# ESP32-H2 register map
Vendor: ESPRESSIF SYSTEMS (SHANGHAI) CO., LTD.; Series: ESP32 H-Series; File version: 11
CPU: RV32IMAC r0p0, little endian, no MPU, no FPU, 0 interrupt priority bits
Address unit: 32 bits
Registers are 32-bit, read-write, reset 0x0 unless marked. A register's access mark holds for its fields unless they carry their own. Offsets are from the block's base; [hi:lo] are bit positions; {n}, {i} and the like mark numbered series.

## ECC — ECC (ECC Hardware Accelerator)
Base 0x6008B000
0x0C MULT_INT_RAW ro — ECC interrupt raw register, valid in level.
  [0] CALC_DONE_INT_RAW — The raw interrupt status bit for the ecc_calc_done_int interrupt
0x10 MULT_INT_ST ro — ECC interrupt status register.
  [0] CALC_DONE_INT_ST — The masked interrupt status bit for the ecc_calc_done_int interrupt
0x14 MULT_INT_ENA — ECC interrupt enable register.
  [0] CALC_DONE_INT_ENA — The interrupt enable bit for the ecc_calc_done_int interrupt
0x18 MULT_INT_CLR wo — ECC interrupt clear register.
  [0] CALC_DONE_INT_CLR — Set this bit to clear the ecc_calc_done_int interrupt
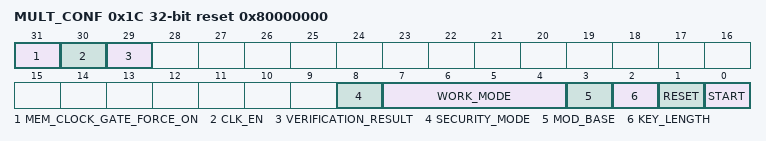
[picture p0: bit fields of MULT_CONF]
0x1C MULT_CONF access per field reset 0x80000000 — ECC configure register
  [31] MEM_CLOCK_GATE_FORCE_ON rw — ECC memory clock gate force on register
  [30] CLK_EN rw — Write 1 to force on register clock gate.
  [29] VERIFICATION_RESULT ro — The verification result bit of ECC Accelerator, only valid when calculation is done.
  [8] SECURITY_MODE rw — Reserved
  [7:4] WORK_MODE rw — The work mode bits of ECC Accelerator. 0: Point Mult Mode. 1: Reserved. 2: Point verification mode. 3: Point Verif+mult mode. 4: Jacobian Point Mult Mode. 5: Point Add Mode. 6: Jacobian Point Verification Mode. 7: Point Verif + Jacobian Mult Mode. 8: mod addition. 9. mod substraction. 10: mod multiplication. 11: mod division.
  [3] MOD_BASE rw — The mod base of mod operation, only valid in work_mode 8-11. 0: n(order of curve). 1: p(mod base of curve)
  [2] KEY_LENGTH rw — The key length mode bit of ECC Accelerator. 0: P-192. 1: P-256.
  [1] RESET wo — Write 1 to reset ECC Accelerator.
  [0] START rw — Write 1 to start caculation of ECC Accelerator. This bit will be self-cleared after the caculatrion is done.
0xFC MULT_DATE reset 0x2207180 — Version control register
  [27:0] DATE — ECC mult version control register
{0x100+4i} K_MEM[{i}] (i=0..7) access not given — The memory that stores k.
{0x120+4i} PX_MEM[{i}] (i=0..7) access not given — The memory that stores Px.
{0x140+4i} PY_MEM[{i}] (i=0..7) access not given — The memory that stores Py.
{0x160+4i} QX_MEM{i} (i=0..7) — The memory that stores Qx
{0x180+4i} QY_MEM{i} (i=0..7) — The memory that stores Qy
{0x1A0+4i} QZ_MEM{i} (i=0..7) — The memory that stores Qz

## GPIO — General Purpose Input/Output
Base 0x60091000
0x00 BT_SELECT — GPIO bit select register
  [31:0] BT_SEL
0x04 OUT — GPIO output register for GPIO0-31
  [31:0] DATA_ORIG
0x08 OUT_W1TS wo — GPIO output set register for GPIO0-31
0x0C OUT_W1TC wo — GPIO output clear register for GPIO0-31
0x1C SDIO_SELECT — GPIO sdio select register
  [7:0] SDIO_SEL
0x20 ENABLE — GPIO output enable register for GPIO0-31
  [31:0] DATA
0x24 ENABLE_W1TS wo — GPIO output enable set register for GPIO0-31
0x28 ENABLE_W1TC wo — GPIO output enable clear register for GPIO0-31
0x38 STRAP ro — pad strapping register
  [15:0] STRAPPING
0x3C IN ro — GPIO input register for GPIO0-31
  [31:0] DATA_NEXT
0x44 STATUS — GPIO interrupt status register for GPIO0-31
  [31:0] INTERRUPT
0x48 STATUS_W1TS wo — GPIO interrupt status set register for GPIO0-31
0x4C STATUS_W1TC wo — GPIO interrupt status clear register for GPIO0-31
0x5C PCPU_INT ro — GPIO PRO_CPU interrupt status register for GPIO0-31
  [31:0] PROCPU_INT
0x60 PCPU_NMI_INT ro — GPIO PRO_CPU(not shielded) interrupt status register for GPIO0-31
  [31:0] PROCPU_NMI_INT
0x64 CPUSDIO_INT ro — GPIO CPUSDIO interrupt status register for GPIO0-31
  [31:0] SDIO_INT
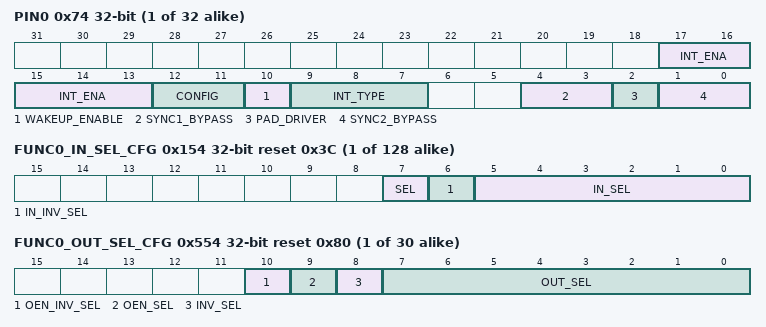
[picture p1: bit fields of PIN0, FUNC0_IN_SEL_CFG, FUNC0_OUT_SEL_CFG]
{0x74+4i} PIN{i} (i=0..31) — GPIO pin configuration register
  [17:13] INT_ENA — set bit 13 to enable CPU interrupt. set bit 14 to enable CPU(not shielded) interrupt.
  [12:11] CONFIG — reserved
  [10] WAKEUP_ENABLE — set this bit to enable GPIO wakeup.(can only wakeup CPU from Light-sleep Mode)
  [9:7] INT_TYPE — set this value to choose interrupt mode. 0:disable GPIO interrupt. 1:trigger at posedge. 2:trigger at negedge. 3:trigger at any edge. 4:valid at low level. 5:valid at high level
  [4:3] SYNC1_BYPASS — set GPIO input_sync1 signal mode. 0:disable. 1:trigger at negedge. 2or3:trigger at posedge.
  [2] PAD_DRIVER — set this bit to select pad driver. 1:open-drain. 0:normal.
  [1:0] SYNC2_BYPASS — set GPIO input_sync2 signal mode. 0:disable. 1:trigger at negedge. 2or3:trigger at posedge.
0x14C STATUS_NEXT ro — GPIO interrupt source register for GPIO0-31
  [31:0] STATUS_INTERRUPT_NEXT
{0x154+4i} FUNC{i}_IN_SEL_CFG (i=0..127) reset 0x3C — GPIO input function configuration register
  [7] SEL — set this bit to bypass GPIO. 1:do not bypass GPIO. 0:bypass GPIO.
  [6] IN_INV_SEL — set this bit to invert input signal. 1:invert. 0:not invert.
  [5:0] IN_SEL — set this value: s=0-34: connect GPIO[s] to this port. s=0x38: set this port always high level. s=0x3C: set this port always low level.
{0x554+4i} FUNC{i}_OUT_SEL_CFG (i=0..29) reset 0x80 — GPIO output function select register
  [10] OEN_INV_SEL — set this bit to invert output enable signal.1:invert.0:not invert.
  [9] OEN_SEL — set this bit to select output enable signal.1:use GPIO_ENABLE_REG[n] as output enable signal.0:use peripheral output enable signal.
  [8] INV_SEL — set this bit to invert output signal.1:invert.0:not invert.
  [7:0] OUT_SEL — The value of the bits: 0<=s<=256. Set the value to select output signal. s=0-127: output of GPIO[n] equals input of peripheral[s]. s=128: output of GPIO[n] equals GPIO_OUT_REG[n].
0x62C CLOCK_GATE reset 0x1 — GPIO clock gate register
  [0] CLK_EN — set this bit to enable GPIO clock gate
0x6FC DATE reset 0x2201120 — GPIO version register
  [27:0] DATE — version register

## Notices in the file
Copyright 2024 Espressif Systems (Shanghai) PTE LTD
Licensed under the Apache License, Version 2.0 (the "License");
you may not use this file except in compliance with the License.
You may obtain a copy of the License at
http://www.apache.org/licenses/LICENSE-2.0
Unless required by applicable law or agreed to in writing, software
distributed under the License is distributed on an "AS IS" BASIS,
WITHOUT WARRANTIES OR CONDITIONS OF ANY KIND, either express or implied.
See the License for the specific language governing permissions and
limitations under the License.
